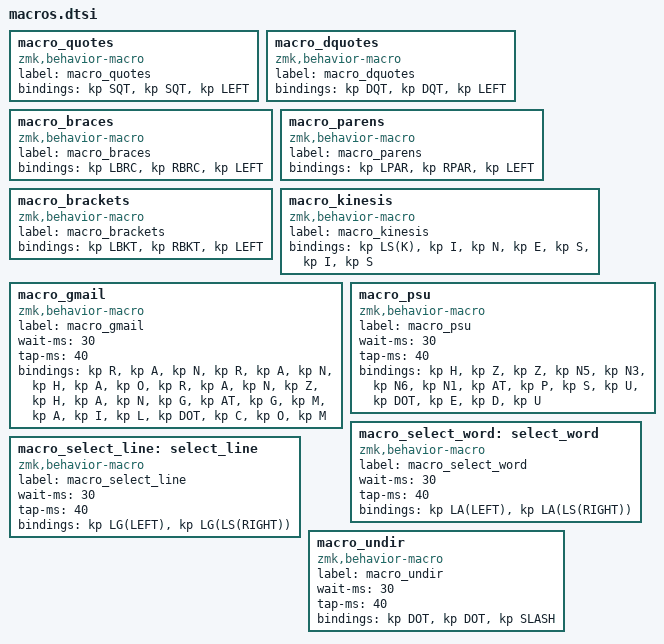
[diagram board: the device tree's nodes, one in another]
  macro_quotes: macro_quotes {
    compatible = "zmk,behavior-macro";
    label = "macro_quotes";
    #binding-cells = <0>;
    bindings = <&kp SQT>, <&kp SQT>, <&kp LEFT>;
  };
  macro_dquotes: macro_dquotes {
    compatible = "zmk,behavior-macro";
    label = "macro_dquotes";
    #binding-cells = <0>;
    bindings = <&kp DQT>, <&kp DQT>, <&kp LEFT>;
  };
  macro_braces: macro_braces {
    compatible = "zmk,behavior-macro";
    label = "macro_braces";
    #binding-cells = <0>;
    bindings = <&kp LBRC>, <&kp RBRC>, <&kp LEFT>;
  };
  macro_parens: macro_parens {
    compatible = "zmk,behavior-macro";
    label = "macro_parens";
    #binding-cells = <0>;
    bindings = <&kp LPAR>, <&kp RPAR>, <&kp LEFT>;
  };
  macro_brackets: macro_brackets {
    compatible = "zmk,behavior-macro";
    label = "macro_brackets";
    #binding-cells = <0>;
    bindings = <&kp LBKT>, <&kp RBKT>, <&kp LEFT>;
  };
  macro_kinesis: macro_kinesis {
    compatible = "zmk,behavior-macro";
    label = "macro_kinesis";
    #binding-cells = <0>;
    bindings = <&kp LS(K)>, <&kp I>, <&kp N>, <&kp E>, <&kp S>, <&kp I>, <&kp S>;
  };
  macro_gmail: macro_gmail {
    compatible = "zmk,behavior-macro";
    label = "macro_gmail";
    #binding-cells = <0>; 
    wait-ms = <30>;
    tap-ms = <40>;
    bindings = <&kp R &kp A &kp N &kp R &kp A &kp N &kp H &kp A &kp O &kp R &kp A &kp N &kp Z &kp H &kp A &kp N &kp G>, <&kp AT>, <&kp G>, <&kp M>, <&kp A>, <&kp I>, <&kp L>, <&kp DOT>, <&kp C>, <&kp O>, <&kp M>;
  };
  macro_psu: macro_psu {
    compatible = "zmk,behavior-macro";
    label = "macro_psu";
    #binding-cells = <0>;
    wait-ms = <30>;
    tap-ms = <40>;
    bindings = <&kp H &kp Z &kp Z &kp N5 &kp N3 &kp N6 &kp N1>
    , <&kp AT>, <&kp P>, <&kp S>
    , <&kp U>, <&kp DOT>, <&kp E>, <&kp D>, <&kp U>;
  };
  macro_select_word: select_word {
    compatible = "zmk,behavior-macro";
    label = "macro_select_word";
    #binding-cells = <0>;
    wait-ms = <30>;
    tap-ms = <40>;
    bindings = <&kp LA(LEFT)>, <&kp LA(LS(RIGHT))>;
  };
  macro_select_line: select_line {
    compatible = "zmk,behavior-macro";
    label = "macro_select_line";
    #binding-cells = <0>;
    wait-ms = <30>;
    tap-ms = <40>;
    bindings = <&kp LG(LEFT)>, <&kp LG(LS(RIGHT))>;
  };
  macro_undir: macro_undir {
    compatible = "zmk,behavior-macro";
    label = "macro_undir";
    #binding-cells = <0>;
    wait-ms = <30>;
    tap-ms = <40>;
    bindings = <&kp DOT &kp DOT &kp SLASH>;
  };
